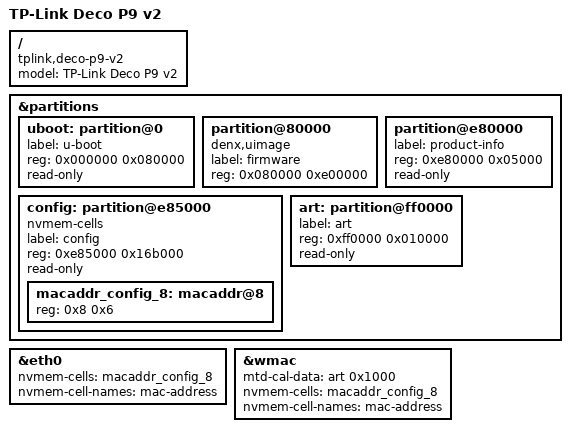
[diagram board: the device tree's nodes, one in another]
// SPDX-License-Identifier: GPL-2.0-or-later OR MIT

#include <dt-bindings/gpio/gpio.h>
#include <dt-bindings/input/input.h>

#include "qca9563_tplink_deco.dtsi"

/ {
	compatible = "tplink,deco-p9-v2", "qca,qca9563";
	model = "TP-Link Deco P9 v2";
};

&partitions {
	uboot: partition@0 {
		label = "u-boot";
		reg = <0x000000 0x080000>;
		read-only;
	};

	partition@80000 {
		compatible = "denx,uimage";
		label = "firmware";
		reg = <0x080000 0xe00000>;
	};
			
	partition@e80000 {
		label = "product-info";
		reg = <0xe80000 0x05000>;
		read-only;
	};

	config: partition@e85000 {
		label = "config";
		reg = <0xe85000 0x16b000>;
		read-only;
	};
			
	art: partition@ff0000 {
		label = "art";
		reg = <0xff0000 0x010000>;
		read-only;
	};
};

&eth0 {
	nvmem-cells = <&macaddr_config_8>;
	nvmem-cell-names = "mac-address";
};

&wmac {
	mtd-cal-data = <&art 0x1000>;

	nvmem-cells = <&macaddr_config_8>;
	nvmem-cell-names = "mac-address";
};

&config {
	compatible = "nvmem-cells";
	#address-cells = <1>;
	#size-cells = <1>;

	macaddr_config_8: macaddr@8 {
		reg = <0x8 0x6>;
	};
};
